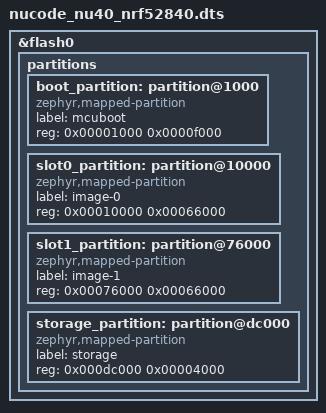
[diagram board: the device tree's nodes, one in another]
/*
 * Copyright (c) 2026 NUCODE Co., Ltd.
 *
 * SPDX-License-Identifier: Apache-2.0
 */

/dts-v1/;
#include "nucode_nu40_nrf52840_common.dtsi"

/* Flash partition table compatible with the onboard UF2 bootloader */

&flash0 {
	partitions {
		ranges;
		#address-cells = <1>;
		#size-cells = <1>;

		/* MCUboot placed after the UF2 bootloader MBR region.
		 * The size of this partition ensures that MCUboot can
		 * be built with CDC ACM support and w/o optimizations.
		 */
		boot_partition: partition@1000 {
			compatible = "zephyr,mapped-partition";
			label = "mcuboot";
			reg = <0x00001000 0x0000f000>;
		};

		slot0_partition: partition@10000 {
			compatible = "zephyr,mapped-partition";
			label = "image-0";
			reg = <0x00010000 0x00066000>;
		};

		slot1_partition: partition@76000 {
			compatible = "zephyr,mapped-partition";
			label = "image-1";
			reg = <0x00076000 0x00066000>;
		};

		storage_partition: partition@dc000 {
			compatible = "zephyr,mapped-partition";
			label = "storage";
			reg = <0x000dc000 0x00004000>;
		};

		/* Onboard UF2 bootloader <0xe0000 0x1c000>
		 *
		 * In addition, the last and second last flash pages
		 * are used by the onboard UF2 bootloader and MBR to store
		 * settings.
		 */
	};
};
